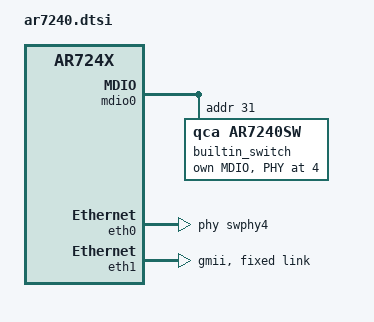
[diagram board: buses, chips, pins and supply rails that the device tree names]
// SPDX-License-Identifier: GPL-2.0-or-later OR MIT

#include "ar724x.dtsi"

/ {
	usb_phy: usb-phy {
		compatible = "qca,ar7200-usb-phy";

		reset-names = "usb-phy", "usb-ohci-dll";
		resets = <&rst 4>, <&rst 3>;

		#phy-cells = <0>;

		status = "disabled";
	};
};

&ahb {
	usb: usb@1b000000 {
		compatible = "generic-ohci";
		reg = <0x1b000000 0x1000>;

		interrupts = <3>;

		resets = <&rst 5>;
		reset-names = "usb-host";

		phy-names = "usb-phy";
		phys = <&usb_phy>;

		status = "disabled";

		#address-cells = <1>;
		#size-cells = <0>;
	};
};

&mdio0 {
	status = "okay";

	compatible = "qca,ar7240-mdio";
	builtin-switch;

	builtin_switch: switch0@1f {
		compatible = "qca,ar7240sw";

		reg = <0x1f>;
		resets = <&rst 8>;
		reset-names = "switch";
		qca,mib-poll-interval = <500>;

		mdio-bus {
			#address-cells = <1>;
			#size-cells = <0>;

			swphy4: ethernet-phy@4 {
				reg = <4>;
				phy-mode = "mii";
			};
		};
	};
};

&eth0 {
	status = "okay";

	compatible = "qca,ar7240-eth", "syscon";

	pll-data = <0x00110000 0x00001099 0x00991099>;

	resets = <&rst 9>;
	reset-names = "mac";
	phy-handle = <&swphy4>;
};

&eth1 {
	compatible = "qca,ar7240-eth", "syscon";

	pll-data = <0x00110000 0x00001099 0x00991099>;

	resets = <&rst 13>;
	reset-names = "mac";

	phy-mode = "gmii";

	fixed-link {
		speed = <1000>;
		full-duplex;
	};
};
